# PIC16F18877 register map
File version: 1.0
Registers are 8-bit, read-write, reset 0x0 unless marked. A register's access mark holds for its fields unless they carry their own. Offsets are from the block's base; [hi:lo] are bit positions; {n}, {i} and the like mark numbered series.

## PORTD
Base 0x0080000F
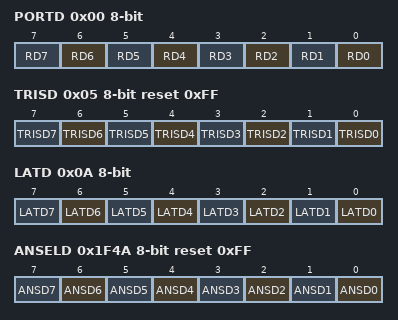
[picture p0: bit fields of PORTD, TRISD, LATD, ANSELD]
0x00 PORTD reset not defined — PORTD, data address 0x00f
  [n] RD{n} (n=0..7)
0x05 TRISD reset 0xFF — TRISD, data address 0x014
  [n] TRISD{n} (n=0..7)
0x0A LATD reset not defined — LATD, data address 0x019
  [n] LATD{n} (n=0..7)
0x1F4A ANSELD reset 0xFF — ANSELD, data address 0x1f59
  [n] ANSD{n} (n=0..7)
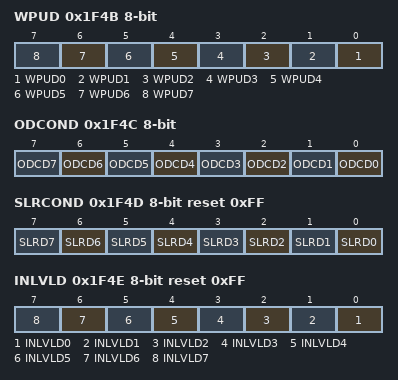
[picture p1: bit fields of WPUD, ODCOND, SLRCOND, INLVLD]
0x1F4B WPUD — WPUD, data address 0x1f5a
  [n] WPUD{n} (n=0..7)
0x1F4C ODCOND — ODCOND, data address 0x1f5b
  [n] ODCD{n} (n=0..7)
0x1F4D SLRCOND reset 0xFF — SLRCOND, data address 0x1f5c
  [n] SLRD{n} (n=0..7)
0x1F4E INLVLD reset 0xFF — INLVLD, data address 0x1f5d
  [n] INLVLD{n} (n=0..7)

## PORTE
Base 0x00800010
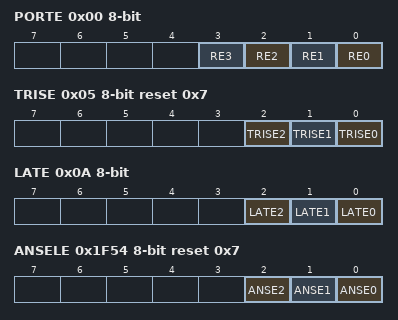
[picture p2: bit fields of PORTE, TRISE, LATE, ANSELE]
0x00 PORTE reset not defined — PORTE, data address 0x010
  [n] RE{n} (n=0..3)
0x05 TRISE reset 0x7 — TRISE, data address 0x015
  [2] TRISE2, [1] TRISE1, [0] TRISE0
0x0A LATE reset not defined — LATE, data address 0x01a
  [2] LATE2, [1] LATE1, [0] LATE0
0x1F54 ANSELE reset 0x7 — ANSELE, data address 0x1f64
  [2] ANSE2, [1] ANSE1, [0] ANSE0
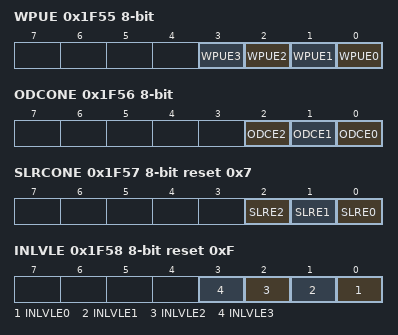
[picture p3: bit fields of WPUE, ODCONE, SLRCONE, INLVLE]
0x1F55 WPUE — WPUE, data address 0x1f65
  [n] WPUE{n} (n=0..3)
0x1F56 ODCONE — ODCONE, data address 0x1f66
  [2] ODCE2, [1] ODCE1, [0] ODCE0
0x1F57 SLRCONE reset 0x7 — SLRCONE, data address 0x1f67
  [2] SLRE2, [1] SLRE1, [0] SLRE0
0x1F58 INLVLE reset 0xF — INLVLE, data address 0x1f68
  [n] INLVLE{n} (n=0..3)
0x1F59 IOCEP — IOCEP, data address 0x1f69
  [3] IOCEP3
0x1F5A IOCEN — IOCEN, data address 0x1f6a
  [3] IOCEN3
0x1F5B IOCEF — IOCEF, data address 0x1f6b
  [3] IOCEF3

## PPS — Peripheral pin select
Base 0x00801E8F
0x00 PPSLOCK — PPSLOCK, data address 0x1e8f
  [0] PPSLOCKED
0x01 INTPPS reset 0x8 — INTPPS, data address 0x1e90
  [3:0] INTPPS
0x02 T0CKIPPS reset 0x4 — T0CKIPPS, data address 0x1e91
  [3:0] T0CKIPPS
0x03 T1CKIPPS reset 0x10 — T1CKIPPS, data address 0x1e92
  [4:0] T1CKIPPS
0x04 T1GPPS reset 0xD — T1GPPS, data address 0x1e93
  [4:0] T1GPPS
0x05 T3CKIPPS reset 0x10 — T3CKIPPS, data address 0x1e94
  [4:0] T3CKIPPS
0x06 T3GPPS reset 0x10 — T3GPPS, data address 0x1e95
  [4:0] T3GPPS
0x07 T5CKIPPS reset 0x12 — T5CKIPPS, data address 0x1e96
  [4:0] T5CKIPPS
0x08 T5GPPS reset 0xC — T5GPPS, data address 0x1e97
  [4:0] T5GPPS
0x0D T2AINPPS reset 0x13 — T2AINPPS, data address 0x1e9c
  [4:0] T2AINPPS
0x0E T4AINPPS reset 0x15 — T4AINPPS, data address 0x1e9d
  [4:0] T4AINPPS
0x0F T6AINPPS reset 0xF — T6AINPPS, data address 0x1e9e
  [4:0] T6AINPPS
0x1A SMT1WINPPS reset 0x10 — SMT1WINPPS, data address 0x1ea9
  [4:0] SMT1WINPPS
0x1B SMT1SIGPPS reset 0x11 — SMT1SIGPPS, data address 0x1eaa
  [4:0] SMT1SIGPPS
0x1C SMT2WINPPS reset 0xC — SMT2WINPPS, data address 0x1eab
  [4:0] SMT2WINPPS
0x1D SMT2SIGPPS reset 0xD — SMT2SIGPPS, data address 0x1eac
  [4:0] SMT2SIGPPS
0x22 CWG1PPS reset 0x8 — CWG1PPS, data address 0x1eb1
  [4:0] CWG1PPS
0x23 CWG2PPS reset 0x9 — CWG2PPS, data address 0x1eb2
  [4:0] CWG2PPS
0x24 CWG3PPS reset 0xA — CWG3PPS, data address 0x1eb3
  [4:0] CWG3PPS
0x29 MDCARLPPS reset 0x3 — MDCARLPPS, data address 0x1eb8
  [4:0] MDCARLPPS
0x2A MDCARHPPS reset 0x4 — MDCARHPPS, data address 0x1eb9
  [4:0] MDCARHPPS
0x2B MDSRCPPS reset 0x5 — MDSRCPPS, data address 0x1eba
  [4:0] MDSRCPPS
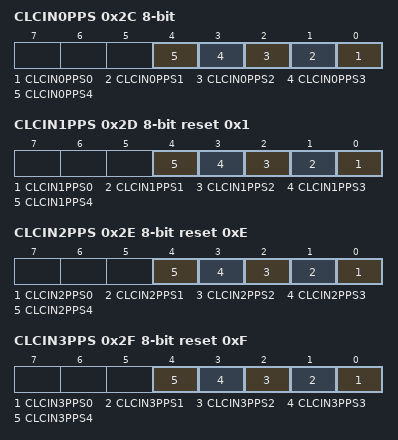
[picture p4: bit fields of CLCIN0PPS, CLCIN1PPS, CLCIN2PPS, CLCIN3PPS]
0x2C CLCIN0PPS — CLCIN0PPS, data address 0x1ebb
  [n] CLCIN0PPS{n} (n=0..4)
0x2D CLCIN1PPS reset 0x1 — CLCIN1PPS, data address 0x1ebc
  [n] CLCIN1PPS{n} (n=0..4)
0x2E CLCIN2PPS reset 0xE — CLCIN2PPS, data address 0x1ebd
  [n] CLCIN2PPS{n} (n=0..4)
0x2F CLCIN3PPS reset 0xF — CLCIN3PPS, data address 0x1ebe
  [n] CLCIN3PPS{n} (n=0..4)
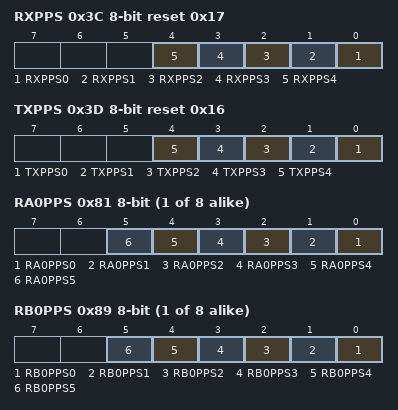
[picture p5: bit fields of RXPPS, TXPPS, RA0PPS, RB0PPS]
0x3C RXPPS reset 0x17 — RXPPS, data address 0x1ecb
  [n] RXPPS{n} (n=0..4)
0x3D TXPPS reset 0x16 — TXPPS, data address 0x1ecc
  [n] TXPPS{n} (n=0..4)
{0x81+i} RA{i}PPS (i=0..7) — RA{i}PPS, data address {0x1F10+i}
  [n] RA{i}PPS{n} (n=0..5)
{0x89+i} RB{i}PPS (i=0..7) — RB{i}PPS, data address {0x1F18+i}
  [n] RB{i}PPS{n} (n=0..5)
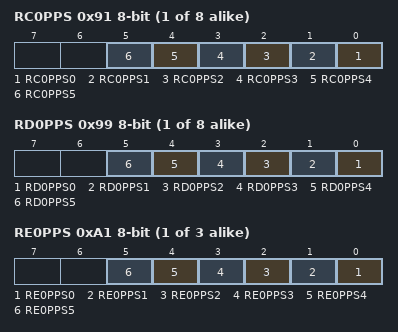
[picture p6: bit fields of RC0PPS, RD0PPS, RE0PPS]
{0x91+i} RC{i}PPS (i=0..7) — RC{i}PPS, data address {0x1F20+i}
  [n] RC{i}PPS{n} (n=0..5)
{0x99+i} RD{i}PPS (i=0..7) — RD{i}PPS, data address {0x1F28+i}
  [n] RD{i}PPS{n} (n=0..5)
{0xA1+i} RE{i}PPS (i=0..2) — RE{i}PPS, data address {0x1F30+i}
  [n] RE{i}PPS{n} (n=0..5)
